# R7FA6T1 register map
Vendor: Renesas; Series: RA6; File version: 1.2
CPU: CM4 r0p1, little endian, MPU, FPU, VTOR, 4 interrupt priority bits
Registers are 8-bit, read-write, reset 0x0 unless marked. A register's access mark holds for its fields unless they carry their own. Offsets are from the block's base; [hi:lo] are bit positions; 'fields as' and 'values as' point back to an identical list; <NAME> marks a mode.

## DMA — DMAC Module Activation
Base 0x40005200
0x00 DMAST — DMA Module Activation Register
  [0] DMST — DMAC Operation Enable
    0=DMAC activation is disabled; 1=DMAC activation is enabled

## DTC — Data Transfer Controller
Base 0x40005400
0x00 DTCCR reset 0x8 — DTC Control Register
  [4] RRS — DTC Transfer Information Read Skip Enable.
    0=Do not skip transfer information read; 1=Skip transfer information read when vector numbers match
0x04 DTCVBR 32-bit — DTC Vector Base Register
  [31:0] DTCVBR — DTC Vector Base Address.Note: A value cannot be set in the lower-order 10 bits. These bits are fixed to 0.
0x0C DTCST — DTC Module Start Register
  [0] DTCST — DTC Module Start
    0=DTC module stop; 1=DTC module start
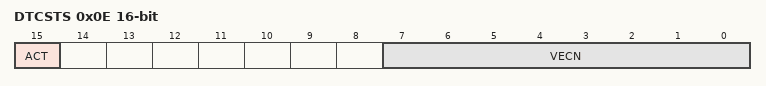
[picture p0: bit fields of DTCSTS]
0x0E DTCSTS 16-bit ro — DTC Status Register
  [15] ACT — DTC Active Flag
    0=DTC transfer operation is not in progress; 1=DTC transfer operation is in progress
  [7:0] VECN — DTC-Activating Vector Number MonitoringThese bits indicate the vector number for the activating source when DTC transfer is in progress.The value is only valid if DTC transfer is in progress (the value of the ACT flag is 1)

## DBG — Debug Function
Base 0x4001B000
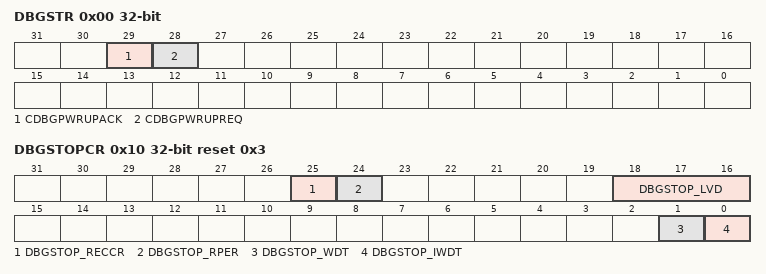
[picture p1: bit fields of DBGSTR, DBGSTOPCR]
0x00 DBGSTR 32-bit ro — Debug Status Register
  [29] CDBGPWRUPACK — Debug power-up acknowledge
    0=Debug power-up request is not acknowledged; 1=Debug power-up request is acknowledged
  [28] CDBGPWRUPREQ — Debug power-up request
    0=OCD is not requesting debug power-up; 1=OCD is requesting debug power-up
0x10 DBGSTOPCR 32-bit reset 0x3 — Debug Stop Control Register
  [25] DBGSTOP_RECCR — Mask bit for RAM ECC error reset/interrupt
    0=Enable RAM ECC error reset/interrupt; 1=Mask RAM ECC error reset/interrupt
  [24] DBGSTOP_RPER — Mask bit for RAM parity error reset/interrupt
    0=Enable RAM parity error reset/interrupt; 1=Mask RAM parity error reset/interrupt
  [18:16] DBGSTOP_LVD — b18: Mask bit for LVD2 reset/interrupt (0:enable / 1:Mask)b17: Mask bit for LVD1 reset/interrupt (0:enable / 1:Mask)b16: Mask bit for LVD0 reset (0:enable / 1:Mask)
  [1] DBGSTOP_WDT — Mask bit for WDT reset/interrupt
    0=Mask WDT reset/interrupt; 1=Enable WDT reset
  [0] DBGSTOP_IWDT — Mask bit for IWDT reset/interrupt
    0=Mask IWDT reset/interrupt; 1=Enable IWDT reset
0x20 TRACECTR 32-bit — Trace Control Register
  [31] ENETBFULL — Enable bit for halt request by ETB full
    0=ETB full does not cause CPU halt; 1=ETB full cause CPU halt

## FCACHE — Flash Cache
Base 0x4001C000
0x100 FCACHEE 16-bit — Flash Cache Enable Register
  [0] FCACHEEN — FCACHE Enable
    0=FCACHE is disabled; 1=FCACHE is enabled
0x104 FCACHEIV 16-bit — Flash Cache Invalidate Register
  [0] FCACHEIV write-1-sets read-modifies — FCACHE Invalidation
    0=(Read)not in progress / (Write) no effect; 1=(Read)in progress /(Write) Starting Cache Invalidation
0x11C FLWT — Flash Wait Cycle Register
  [2:0] FLWT — Flash Wait Cycle
    0=0 wait (ICLK<=80MHz); 1=1 wait (80MHz < ICLK <=160MHz); 2=2 waits (160MHz < ICLK <=240MHz); other=others (Setting prohibited)

## PORT0 — Port 0 Control Registers
Base 0x40040000
Same registers: PORT5 0x400400A0, PORT6 0x400400C0, PORT7 0x400400E0
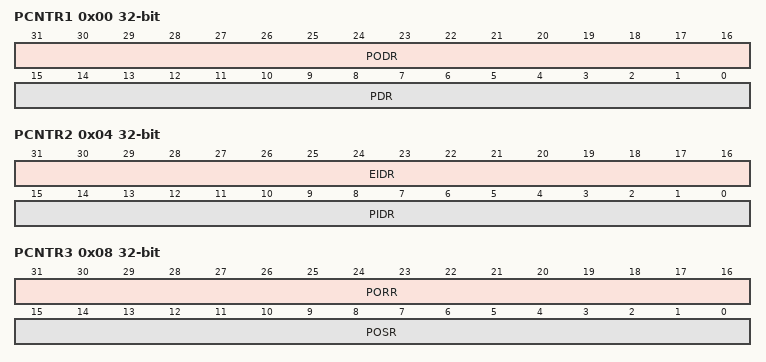
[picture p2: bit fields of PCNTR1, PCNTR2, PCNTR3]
0x00 PCNTR1 32-bit — Port Control Register 1
  [31:16] PODR — Pmn Output Data
    0=Low output; 1=High output
  [15:0] PDR — Pmn Direction
    0=Input (functions as an input pin); 1=Output (functions as an output pin)
0x00 PODR 16-bit (alternate view of PCNTR1) — Output data register
  [15:0] PODR — Pmn Output Data
    0=Low output; 1=High output
0x02 PDR 16-bit (alternate view of PCNTR1) — Data direction register
  [15:0] PDR — Pmn Direction
    values as PCNTR1.PDR
0x04 PCNTR2 32-bit ro (reset mask 0xFFFF0000) — Port Control Register 2
  [31:16] EIDR — Pmn Event Input Data
    0=Low input; 1=High input
  [15:0] PIDR — Pmn Input Data
    0=Low input; 1=High input
0x06 PIDR 16-bit ro reset not defined (alternate view of PCNTR2) — Input data register
  [15:0] PIDR — Pmn Input Data
    0=Low input; 1=High input
0x08 PCNTR3 32-bit wo — Port Control Register 3
  [31:16] PORR — Pmn Output Reset
    0=No affect to output; 1=Low output
  [15:0] POSR — Pmn Output Set
    0=No affect to output; 1=High output
0x08 PORR 16-bit wo (alternate view of PCNTR3) — Output reset register
  [15:0] PORR — Pmn Output Reset
    0=No affect to output; 1=Low output
0x0A POSR 16-bit wo (alternate view of PCNTR3) — Output set register
  [15:0] POSR — Pmn Output Set
    0=No affect to output; 1=High output

## PORT1 — Port 1 Control Registers
Base 0x40040020
Same registers: PORT2 0x40040040, PORT3 0x40040060, PORT4 0x40040080
Registers as PORT0; these are added or differ:
0x04 EIDR 16-bit ro reset not defined (alternate view of PCNTR2) — Event input data register
  [15:0] EIDR — Pmn Event Input Data
    0=Low input; 1=High input
0x08 PORR 16-bit wo (alternate view of PCNTR3) — Output set register
  [15:0] PORR — Pmn Output Reset
    0=No affect to output; 1=Low output
0x0A POSR 16-bit wo (alternate view of PCNTR3) — Output reset register
  [15:0] POSR — Pmn Output Set
    0=No affect to output; 1=High output
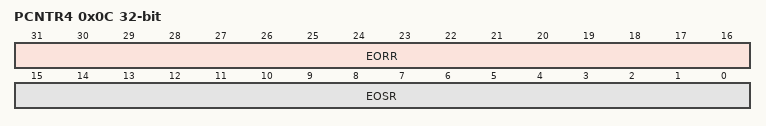
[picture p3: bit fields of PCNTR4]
0x0C PCNTR4 32-bit — Port Control Register 4
  [31:16] EORR — Pmn Event Output Reset
    0=No affect to output; 1=Low output
  [15:0] EOSR — Pmn Event Output Set
    0=No affect to output; 1=High output
0x0C EORR 16-bit (alternate view of PCNTR4) — Event output set register
  [15:0] EORR — Pmn Event Output Reset
    0=No affect to output; 1=Low output
0x0E EOSR 16-bit (alternate view of PCNTR4) — Event output reset register
  [15:0] EOSR — Pmn Event Output Set
    0=No affect to output; 1=High output
